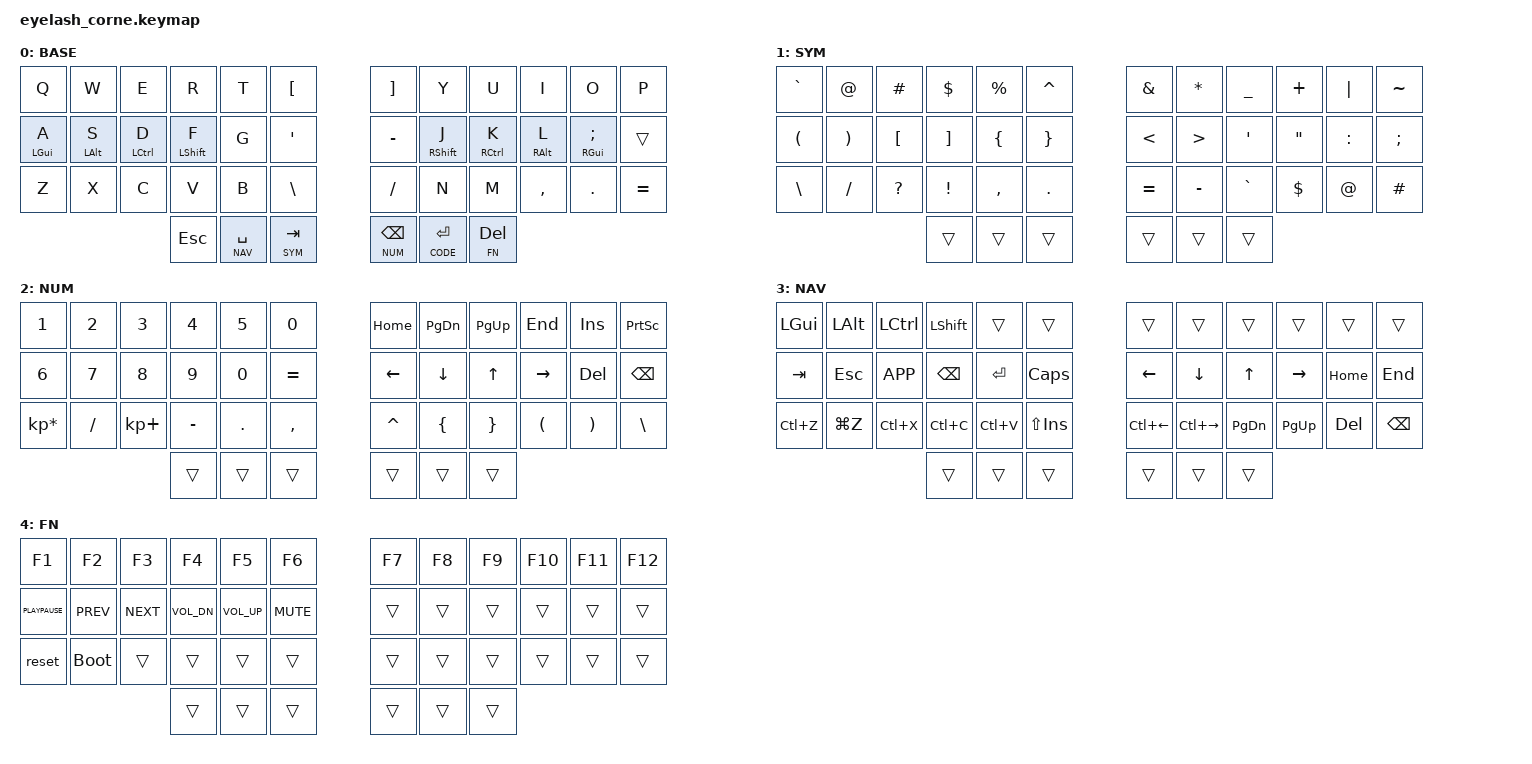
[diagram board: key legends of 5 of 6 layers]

/* ZMK keymap for Corne + nice!nano v2 + nice!view */

&mt { tapping-term-ms = <200>; };
&lt { tapping-term-ms = <200>; };

#define HM_A &mt LGUI A
#define HM_S &mt LALT S
#define HM_D &mt LCTRL D
#define HM_F &mt LSHFT F
#define HM_J &mt RSHFT J
#define HM_K &mt RCTRL K
#define HM_L &mt RALT L
#define HM_SCLN &mt RGUI SEMI

#define LT_NAV_SPC &lt NAV SPACE
#define LT_SYM_TAB &lt SYM TAB
#define LT_NUM_BSP &lt NUM BSPC
#define LT_CODE_ENT &lt CODE ENTER
#define LT_FN_DEL &lt FN DEL

/ {
    behaviors {
        macro_paren: macro_paren { compatible = "zmk,behavior-macro"; label = "PAR()"; #binding-cells = <0>; bindings = <&kp LPAR &kp RPAR &kp LEFT>; };
        macro_brack: macro_brack { compatible = "zmk,behavior-macro"; label = "BRK[]"; #binding-cells = <0>; bindings = <&kp LBKT &kp RBKT &kp LEFT>; };
        macro_brace: macro_brace { compatible = "zmk,behavior-macro"; label = "BRC{}"; #binding-cells = <0>; bindings = <&kp LBRC &kp RBRC &kp LEFT>; };
        macro_backtickpair: macro_backtickpair { compatible = "zmk,behavior-macro"; label = "BT``"; #binding-cells = <0>; bindings = <&kp GRAVE &kp GRAVE &kp LEFT>; };
        macro_dollar_brace: macro_dollar_brace { compatible = "zmk,behavior-macro"; label = "${}"; #binding-cells = <0>; bindings = <&kp DOLLAR &kp LBRC &kp RBRC &kp LEFT>; };
        macro_arrow_fn: macro_arrow_fn { compatible = "zmk,behavior-macro"; label = "=>"; #binding-cells = <0>; bindings = <&kp SPACE &kp EQUAL &kp RARROW &kp SPACE>; };
        macro_php_ptr: macro_php_ptr { compatible = "zmk,behavior-macro"; label = "->"; #binding-cells = <0>; bindings = <&kp MINUS &kp RARROW>; };
        macro_php_scope: macro_php_scope { compatible = "zmk,behavior-macro"; label = "::"; #binding-cells = <0>; bindings = <&kp COLON &kp COLON>; };
        macro_log: macro_log { compatible = "zmk,behavior-macro"; label = "console.log()"; #binding-cells = <0>; bindings = <&kp C &kp O &kp N &kp S &kp O &kp L &kp E &kp DOT &kp L &kp O &kp G &kp LPAR &kp RPAR &kp SEMI>; };
        macro_php_tags: macro_php_tags { compatible = "zmk,behavior-macro"; label = "<?php ?>"; #binding-cells = <0>; bindings = <&kp LT &kp QMARK &kp P &kp H &kp P &kp ENTER &kp ENTER &kp QMARK &kp GT>; };
        macro_echo: macro_echo { compatible = "zmk,behavior-macro"; label = "echo ''"; #binding-cells = <0>; bindings = <&kp E &kp C &kp H &kp O &kp SPACE &kp SQT &kp SQT &kp SEMI &kp LEFT>; };
    };
};

/ {
  keymap {
    compatible = "zmk,keymap";

    default_layer {
      label = "BASE";
      bindings = <
        &kp Q  &kp W  &kp E  &kp R  &kp T  &kp LBKT           &kp RBKT &kp Y  &kp U  &kp I  &kp O  &kp P
        HM_A   HM_S   HM_D   HM_F   &kp G  &kp SQT            &kp MINUS HM_J  HM_K  HM_L  HM_SCLN &trans
        &kp Z  &kp X  &kp C  &kp V  &kp B  &kp BSLH           &kp SLASH &kp N &kp M &kp COMMA &kp DOT &kp EQUAL
                           &kp ESC  LT_NAV_SPC  LT_SYM_TAB   LT_NUM_BSP  LT_CODE_ENT  LT_FN_DEL
      >;
    };

    sym_layer {
      label = "SYM";
      bindings = <
        &kp GRAVE &kp AT &kp HASH &kp DLLR &kp PRCNT &kp CARET   &kp AMPS &kp ASTERISK &kp UNDERSCORE &kp PLUS &kp PIPE &kp TILDE
        &kp LPAR &kp RPAR &kp LBKT &kp RBKT &kp LBRC &kp RBRC   &kp LT &kp GT &kp SQT &kp DQT &kp COLON &kp SEMI
        &kp BSLH &kp SLASH &kp QMARK &kp EXCL &kp COMMA &kp DOT &kp EQUAL &kp MINUS &kp GRAVE &kp DLLR &kp AT &kp HASH
                           &trans &trans &trans    &trans &trans &trans
      >;
    };

    num_layer {
      label = "NUM";
      bindings = <
        &kp N1 &kp N2 &kp N3 &kp N4 &kp N5 &kp N0    &kp HOME &kp PG_DN &kp PG_UP &kp END &kp INS &kp PSCRN
        &kp N6 &kp N7 &kp N8 &kp N9 &kp N0 &kp EQUAL &kp LEFT &kp DOWN &kp UP &kp RIGHT &kp DEL &kp BSPC
        &kp KP_MULTIPLY &kp SLASH &kp KP_PLUS &kp MINUS &kp DOT &kp COMMA  &kp CARET &kp LBRC &kp RBRC &kp LPAR &kp RPAR &kp BSLH
                           &trans &trans &trans    &trans &trans &trans
      >;
    };

    nav_layer {
      label = "NAV";
      bindings = <
        &kp LGUI &kp LALT &kp LCTRL &kp LSHFT &trans &trans   &trans &trans &trans &trans &trans &trans
        &kp TAB &kp ESC &kp K_APP &kp BSPC &kp ENTER &kp CAPS  &kp LEFT &kp DOWN &kp UP &kp RIGHT &kp HOME &kp END
        &kp LC(Z) &kp LG(Z) &kp LC(X) &kp LC(C) &kp LC(V) &kp LS(INS)  &kp LC(LEFT) &kp LC(RIGHT) &kp PG_DN &kp PG_UP &kp DEL &kp BSPC
                           &trans &trans &trans    &trans &trans &trans
      >;
    };

    fn_layer {
      label = "FN";
      bindings = <
        &kp F1 &kp F2 &kp F3 &kp F4 &kp F5 &kp F6    &kp F7 &kp F8 &kp F9 &kp F10 &kp F11 &kp F12
        &kp C_PLAYPAUSE &kp C_PREV &kp C_NEXT &kp C_VOL_DN &kp C_VOL_UP &kp C_MUTE   &trans &trans &trans &trans &trans &trans
        &reset &bootloader &trans &trans &trans &trans   &trans &trans &trans &trans &trans &trans
                           &trans &trans &trans    &trans &trans &trans
      >;
    };

    code_layer {
      label = "CODE";
      bindings = <
        &macro_arrow_fn &macro_php_ptr &macro_php_scope &kp EQUAL &kp EXCL &kp MINUS
        &macro_brack &macro_paren &macro_brace &kp LT &macro_backtickpair &macro_dollar_brace
        &macro_log &trans &trans &trans &trans &trans   &trans &trans &trans &trans &macro_php_tags &macro_echo
                           &trans &trans &trans    &trans &trans &trans
      >;
    };
  };
};
